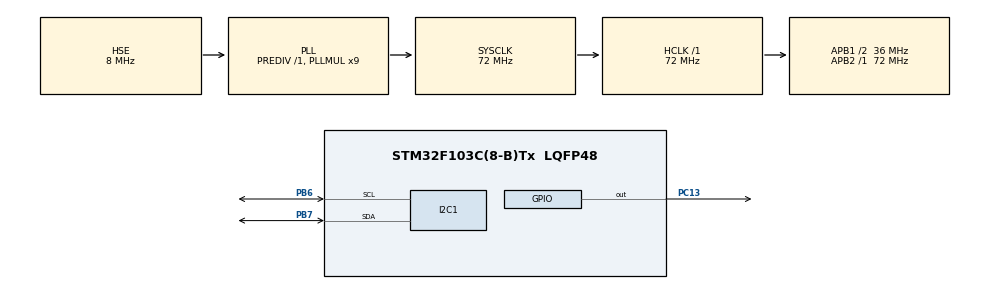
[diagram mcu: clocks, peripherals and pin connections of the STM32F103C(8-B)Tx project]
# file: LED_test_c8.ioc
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Mcu.Family=STM32F1
Mcu.Name=STM32F103C(8-B)Tx
Mcu.Package=LQFP48
NVIC.PriorityGroup=NVIC_PRIORITYGROUP_4
PA13.Mode=Serial_Wire
PA13.Signal=SYS_JTMS-SWDIO
PA14.Mode=Serial_Wire
PA14.Signal=SYS_JTCK-SWCLK
PB6.Mode=I2C
PB6.Signal=I2C1_SCL
PB7.Mode=I2C
PB7.Signal=I2C1_SDA
PC13-TAMPER-RTC.GPIO_Speed=GPIO_SPEED_FREQ_MEDIUM
PC13-TAMPER-RTC.Signal=GPIO_Output
PC14-OSC32_IN.Mode=LSE-External-Oscillator
PC14-OSC32_IN.Signal=RCC_OSC32_IN
PC15-OSC32_OUT.Mode=LSE-External-Oscillator
PC15-OSC32_OUT.Signal=RCC_OSC32_OUT
PD0-OSC_IN.Mode=HSE-External-Oscillator
PD0-OSC_IN.Signal=RCC_OSC_IN
PD1-OSC_OUT.Mode=HSE-External-Oscillator
PD1-OSC_OUT.Signal=RCC_OSC_OUT
ProjectManager.HeapSize=0x200
ProjectManager.StackSize=0x400
ProjectManager.TargetToolchain=TrueSTUDIO
RCC.AHBFreq_Value=72000000
RCC.APB1CLKDivider=RCC_HCLK_DIV2
RCC.APB1Freq_Value=36000000
RCC.APB1TimFreq_Value=72000000
RCC.APB2Freq_Value=72000000
RCC.APB2TimFreq_Value=72000000
RCC.HCLKFreq_Value=72000000
RCC.PLLMUL=RCC_PLL_MUL9
RCC.PLLSourceVirtual=RCC_PLLSOURCE_HSE
RCC.RTCClockSelection=RCC_RTCCLKSOURCE_LSE
RCC.SYSCLKFreq_VALUE=72000000
RCC.SYSCLKSource=RCC_SYSCLKSOURCE_PLLCLK
RCC.USBFreq_Value=72000000
RTC.Date=19
RTC.Format=RTC_FORMAT_BCD
RTC.Month=RTC_MONTH_FEBRUARY
RTC.WeekDay=RTC_WEEKDAY_WEDNESDAY
RTC.Year=20
VP_RTC_VS_RTC_Activate.Mode=RTC_Enabled
VP_RTC_VS_RTC_Calendar.Mode=RTC_Calendar
board=custom

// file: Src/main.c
/* USER CODE BEGIN Header */
/**
  ******************************************************************************
  * @file           : main.c
  * @brief          : Main program body
  ******************************************************************************
  * @attention
  *
  * <h2><center>&copy; Copyright (c) 2020 STMicroelectronics.
  * All rights reserved.</center></h2>
  *
  * This software component is licensed by ST under BSD 3-Clause license,
  * the "License"; You may not use this file except in compliance with the
  * License. You may obtain a copy of the License at:
  *                        opensource.org/licenses/BSD-3-Clause
  *
  ******************************************************************************
  */
/* USER CODE END Header */

#include "main.h"
#include "i2c.h"
#include "rtc.h"
#include "gpio.h"

/* USER CODE BEGIN Includes */
#include "oleds.h"
#include "stdio.h"
/* USER CODE END Includes */

/* USER CODE BEGIN PTD */
RTC_DateTypeDef sdatestructure;
RTC_TimeTypeDef stimestructure;
/* USER CODE END PTD */

void SystemClock_Config(void);

int main(void)
{

  /* MCU Configuration--------------------------------------------------------*/

  /* Reset of all peripherals, Initializes the Flash interface and the Systick. */
  HAL_Init();

  /* Configure the system clock */
  SystemClock_Config();

  /* Initialize all configured peripherals */
  MX_GPIO_Init();
  MX_I2C1_Init();
  MX_RTC_Init();
  /* USER CODE BEGIN 2 */
  OLED_Init();
  OLED_CLS();
//  OLED_ShowStr(1,0,(uint8_t *)"Voltage:",1);
//  OLED_ShowStr(1,2,(uint8_t *)"Designed by Joe_joe",1);
  /* USER CODE END 2 */

  /* Infinite loop */
  while (1)
  {

    /* USER CODE BEGIN 3 */
//	  HAL_GPIO_TogglePin(GPIOC,GPIO_PIN_13);
//	  HAL_Delay(500);
//	  HAL_GPIO_TogglePin(GPIOC,GPIO_PIN_13);
//	  HAL_Delay(500);
	  HAL_RTC_GetTime(&hrtc,&stimestructure,RTC_FORMAT_BCD);
	  HAL_RTC_GetDate(&hrtc,&sdatestructure,RTC_FORMAT_BCD);
	  OLED_ShowNum(1,3,stimestructure.Hours,3,1);
	  OLED_ShowNum(50,3,stimestructure.Minutes,3,1);
	  OLED_ShowNum(90,3,stimestructure.Seconds,3,1);
	  HAL_Delay(1000);

  }
  /* USER CODE END 3 */
}

void SystemClock_Config(void)
{
  RCC_OscInitTypeDef RCC_OscInitStruct = {0};
  RCC_ClkInitTypeDef RCC_ClkInitStruct = {0};
  RCC_PeriphCLKInitTypeDef PeriphClkInit = {0};

  /** Initializes the CPU, AHB and APB busses clocks
  */
  RCC_OscInitStruct.OscillatorType = RCC_OSCILLATORTYPE_HSE|RCC_OSCILLATORTYPE_LSE;
  RCC_OscInitStruct.HSEState = RCC_HSE_ON;
  RCC_OscInitStruct.HSEPredivValue = RCC_HSE_PREDIV_DIV1;
  RCC_OscInitStruct.LSEState = RCC_LSE_ON;
  RCC_OscInitStruct.HSIState = RCC_HSI_ON;
  RCC_OscInitStruct.PLL.PLLState = RCC_PLL_ON;
  RCC_OscInitStruct.PLL.PLLSource = RCC_PLLSOURCE_HSE;
  RCC_OscInitStruct.PLL.PLLMUL = RCC_PLL_MUL9;
  if (HAL_RCC_OscConfig(&RCC_OscInitStruct) != HAL_OK)
  {
    Error_Handler();
  }
  /** Initializes the CPU, AHB and APB busses clocks
  */
  RCC_ClkInitStruct.ClockType = RCC_CLOCKTYPE_HCLK|RCC_CLOCKTYPE_SYSCLK
                              |RCC_CLOCKTYPE_PCLK1|RCC_CLOCKTYPE_PCLK2;
  RCC_ClkInitStruct.SYSCLKSource = RCC_SYSCLKSOURCE_PLLCLK;
  RCC_ClkInitStruct.AHBCLKDivider = RCC_SYSCLK_DIV1;
  RCC_ClkInitStruct.APB1CLKDivider = RCC_HCLK_DIV2;
  RCC_ClkInitStruct.APB2CLKDivider = RCC_HCLK_DIV1;

  if (HAL_RCC_ClockConfig(&RCC_ClkInitStruct, FLASH_LATENCY_2) != HAL_OK)
  {
    Error_Handler();
  }
  PeriphClkInit.PeriphClockSelection = RCC_PERIPHCLK_RTC;
  PeriphClkInit.RTCClockSelection = RCC_RTCCLKSOURCE_LSE;
  if (HAL_RCCEx_PeriphCLKConfig(&PeriphClkInit) != HAL_OK)
  {
    Error_Handler();
  }
}

void Error_Handler(void)
{
}

/************************ (C) COPYRIGHT STMicroelectronics *****END OF FILE****/
